# ESP32S31_RADIO register map
Vendor: Espressif; Series: ESP32-S31; File version: 3.52
Registers are 32-bit, read-write, no defined reset value unless marked. A register's access mark holds for its fields unless they carry their own. Offsets are from the block's base; [hi:lo] are bit positions.

## PHY_RX_DCO_ORACLE — RX-DCO calibration control word recovered from complete pinned S31 blob and rev0 ROM calibration bodies.
Base 0x20100000
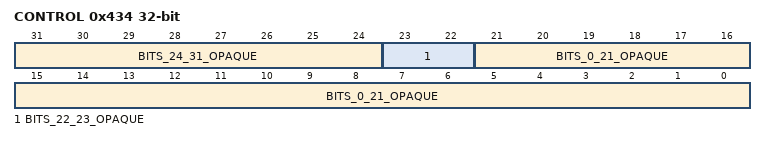
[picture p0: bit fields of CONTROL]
0x434 CONTROL — Project-assigned name. Complete phy_xtal_duty_cal and RX-DCO calibration bodies save, clear and restore bits 23:22 around measurement.
  [31:24] BITS_24_31_OPAQUE — Opaque: meaning not established. Observed source use; the individual hardware meaning is unknown.
  [23:22] BITS_22_23_OPAQUE — Opaque: meaning not established. Two-bit field preserved around the complete bounded RX-DCO measurement graph.
  [21:0] BITS_0_21_OPAQUE — Opaque: meaning not established. Observed source use; the individual hardware meaning is unknown.

## WIFI_MAC_LOCAL_TIME — Free-running Wi-Fi MAC local-time counter, read-only and without read side effects. Complete libpp[lmac.o]::lmacAdjustTimestamp subtracts the receive timestamp a received frame carries from this word as the frame's age and, while the station slept, rewrites that timestamp as this word minus a TU-scaled sleep interval; libpp[pm_twt.o]::pm_twt_set_target_wdev_time, libpp[pm_coex.o]::pm_get_null_max_tx_time and libpp[pm_coex.o]::pm_coex_recalculate_wifi_time_slice read it as the MAC's current time. The PHY SDM deadline samples the same word. Its unit and rate against the system timer are not established.
Base 0x2010D800
0x00 COUNTER ro — Project-assigned name. The MAC local-time counter. Complete phy_wait_i2c_sdm_stable samples it before and after each independently completed PHY-I2C read.
  [31:0] VALUE — Project-assigned name. Full-width wrapping counter value in microseconds, at the system timer's rate; receive timestamps are readings of it.

## PHY_CLOCK_ORACLE — OPAQUE PHY clock-gate registers recovered from complete no-call ROM/blob leaves.
Base 0x20100000
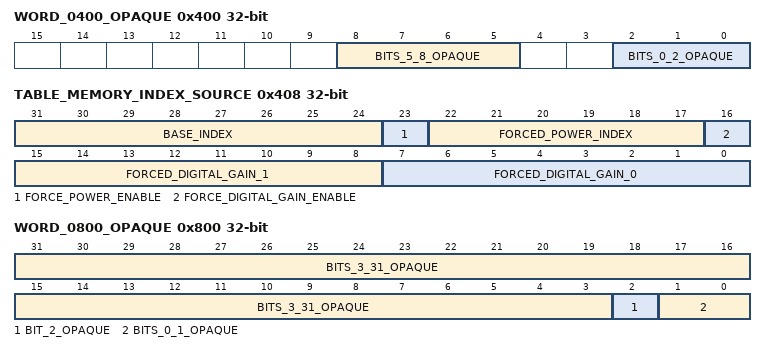
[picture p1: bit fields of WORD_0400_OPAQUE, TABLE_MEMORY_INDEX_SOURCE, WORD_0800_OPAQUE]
0x400 WORD_0400_OPAQUE wo — Opaque: meaning not established. ROM writes 0x1e7 to open and the blob writes zero to close.
  [8:5] BITS_5_8_OPAQUE — Opaque: meaning not established. Observed source use; the individual hardware meaning is unknown.
  [2:0] BITS_0_2_OPAQUE — Opaque: meaning not established. Observed source use; the individual hardware meaning is unknown.
0x408 TABLE_MEMORY_INDEX_SOURCE — Project-assigned name. Shared word contains the table-memory base index and the complete phy_force_pwr_index controls.
  [31:24] BASE_INDEX — Project-assigned name. Eight-bit table-memory base index; the complete front-end initializer writes 0xa0.
  [23] FORCE_POWER_ENABLE — Project-assigned name. Complete phy_force_pwr_index replaces bit 23 with the low bit of its first argument.
  [22:17] FORCED_POWER_INDEX — Project-assigned name. Complete phy_force_pwr_index replaces bits 22:17 with the low six bits of its second argument.
  [16] FORCE_DIGITAL_GAIN_ENABLE — Project-assigned name.
  [15:8] FORCED_DIGITAL_GAIN_1 — Project-assigned name.
  [7:0] FORCED_DIGITAL_GAIN_0 — Project-assigned name.
0x800 WORD_0800_OPAQUE — Opaque: meaning not established. ROM sets bits 1:0 and the blob clears them.
  [31:3] BITS_3_31_OPAQUE — Opaque: meaning not established. Observed source use; the individual hardware meaning is unknown.
  [2] BIT_2_OPAQUE — Opaque: meaning not established. The phy_bb_init parent sets bit 2 before calibration; the individual hardware meaning remains unknown.
  [1:0] BITS_0_1_OPAQUE — Opaque: meaning not established. Two-bit open/close mask; individual meanings are unknown.
    on write: 0=CLOSED; 3=OPEN
0x7C80 WORD_7C80_OPAQUE wo — Opaque: meaning not established. ROM writes all ones to open and the blob writes zero to close.
  [31:0] STATE — Project-assigned name. Complete observed baseband clock-gate images; constituent gate meanings remain unknown.
    on write: 0=CLOSED; 0xFFFFFFFF=OPEN
